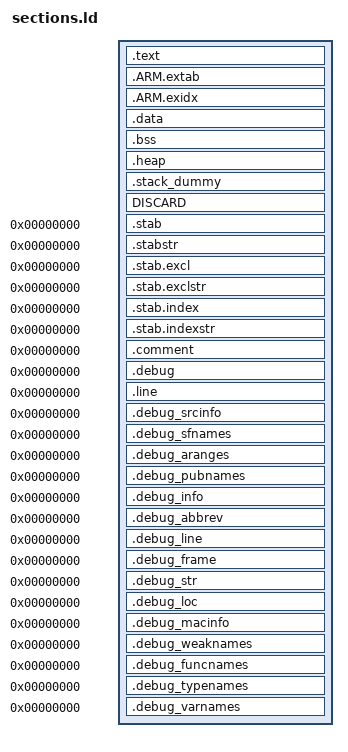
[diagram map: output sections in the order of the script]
/* Based on the linker script from CMSIS for GCC for ARM Embedded Processors.
 * Should be included after memory layout script.
 */

/* Library configurations */
GROUP(libgcc.a libc.a libm.a)

/* Linker script to place sections and symbol values. Should be used together
 * with other linker script that defines memory regions FLASH and RAM.
 * It references following symbols, which must be defined in code:
 *   Reset_Handler : Entry of reset handler
 * 
 * It defines following symbols, which code can use without definition:
 *   __exidx_start
 *   __exidx_end
 *   __etext
 *   __data_start__
 *   __preinit_array_start
 *   __preinit_array_end
 *   __init_array_start
 *   __init_array_end
 *   __fini_array_start
 *   __fini_array_end
 *   __data_end__
 *   __bss_start__
 *   __bss_end__
 *   __end__
 *   end
 *   __HeapLimit
 *   __StackLimit
 *   __StackTop
 *   __stack
 */
 
/* Used in QEMU, the embedded images entry point is in the interrupts table */
ENTRY(Reset_Handler)

SECTIONS
{
	.text :
	{
		KEEP(*(.core_isr_vectors))
		KEEP(*(.family_isr_vectors))
		KEEP(*(.device_isr_vectors))
		KEEP(*(.isr_vector))
		*(.text*)

		KEEP(*(.init))
		KEEP(*(.fini))

		/* .ctors */
		*crtbegin.o(.ctors)
		*crtbegin?.o(.ctors)
		*(EXCLUDE_FILE(*crtend?.o *crtend.o) .ctors)
		*(SORT(.ctors.*))
		*(.ctors)

		/* .dtors */
 		*crtbegin.o(.dtors)
 		*crtbegin?.o(.dtors)
 		*(EXCLUDE_FILE(*crtend?.o *crtend.o) .dtors)
 		*(SORT(.dtors.*))
 		*(.dtors)

		. = ALIGN(4);
		/* preinit data */
		PROVIDE_HIDDEN (__preinit_array_start = .);
		KEEP(*(.preinit_array))
		PROVIDE_HIDDEN (__preinit_array_end = .);

		. = ALIGN(4);
		/* init data */
		PROVIDE_HIDDEN (__init_array_start = .);
		KEEP(*(SORT(.init_array.*)))
		KEEP(*(.init_array))
		PROVIDE_HIDDEN (__init_array_end = .);


		. = ALIGN(4);
		/* finit data */
		PROVIDE_HIDDEN (__fini_array_start = .);
		KEEP(*(SORT(.fini_array.*)))
		KEEP(*(.fini_array))
		PROVIDE_HIDDEN (__fini_array_end = .);

		*(.rodata*)

		KEEP(*(.eh_frame*))
	} > FLASH

	.ARM.extab : 
	{
		*(.ARM.extab* .gnu.linkonce.armextab.*)
	} > FLASH

	__exidx_start = .;
	.ARM.exidx :
	{
		*(.ARM.exidx* .gnu.linkonce.armexidx.*)
	} > FLASH
	__exidx_end = .;

	__etext = .;
		
	/* The initialised data section is stored immediately 
	at the end of the text section */
	.data : AT (__etext)
	{
		__data_start__ = .;
		*(vtable)
		*(.data*)

		. = ALIGN(4);
		/* init_array/fini_array moved to flash, align preserved */
		
		KEEP(*(.jcr*))
		. = ALIGN(4);
		/* All data end */
		__data_end__ = .;

	} > RAM

	.bss :
	{
		. = ALIGN(4);
		__bss_start__ = .;
		*(.bss*)
		*(COMMON)
		. = ALIGN(4);
		__bss_end__ = .;
	} > RAM
	
	.heap (COPY):
	{
		__end__ = .;
		end = __end__;
		*(.heap*)
		__HeapLimit = .;
	} > RAM

	/* .stack_dummy section doesn't contains any symbols. It is only
	 * used for linker to calculate size of stack sections, and assign
	 * values to stack symbols later */
	.stack_dummy (COPY):
	{
		*(.stack*)
	} > RAM

	/* Set stack top to end of RAM, and stack limit move down by
	 * size of stack_dummy section */
	__StackTop = ORIGIN(RAM) + LENGTH(RAM);
	__StackLimit = __StackTop - SIZEOF(.stack_dummy);
	PROVIDE(__stack = __StackTop);
	
	/* Check if data + heap + stack exceeds RAM limit */
	ASSERT(__StackLimit >= __HeapLimit, "region RAM overflowed with stack")
	
	
	/* The following is from F4 linker scripts */
	
	/* after that it's only debugging information. */
    
    /* remove the debugging information from the standard libraries */
    DISCARD :
    {
     libc.a ( * )
     libm.a ( * )
     libgcc.a ( * )
     }
  
  
    /* Stabs debugging sections.  */
    .stab          0 : { *(.stab) }
    .stabstr       0 : { *(.stabstr) }
    .stab.excl     0 : { *(.stab.excl) }
    .stab.exclstr  0 : { *(.stab.exclstr) }
    .stab.index    0 : { *(.stab.index) }
    .stab.indexstr 0 : { *(.stab.indexstr) }
    .comment       0 : { *(.comment) }
    /* DWARF debug sections.
       Symbols in the DWARF debugging sections are relative to the beginning
       of the section so we begin them at 0.  */
    /* DWARF 1 */
    .debug          0 : { *(.debug) }
    .line           0 : { *(.line) }
    /* GNU DWARF 1 extensions */
    .debug_srcinfo  0 : { *(.debug_srcinfo) }
    .debug_sfnames  0 : { *(.debug_sfnames) }
    /* DWARF 1.1 and DWARF 2 */
    .debug_aranges  0 : { *(.debug_aranges) }
    .debug_pubnames 0 : { *(.debug_pubnames) }
    /* DWARF 2 */
    .debug_info     0 : { *(.debug_info .gnu.linkonce.wi.*) }
    .debug_abbrev   0 : { *(.debug_abbrev) }
    .debug_line     0 : { *(.debug_line) }
    .debug_frame    0 : { *(.debug_frame) }
    .debug_str      0 : { *(.debug_str) }
    .debug_loc      0 : { *(.debug_loc) }
    .debug_macinfo  0 : { *(.debug_macinfo) }
    /* SGI/MIPS DWARF 2 extensions */
    .debug_weaknames 0 : { *(.debug_weaknames) }
    .debug_funcnames 0 : { *(.debug_funcnames) }
    .debug_typenames 0 : { *(.debug_typenames) }
    .debug_varnames  0 : { *(.debug_varnames) }    
   
}
